# ECM3532 register map
Vendor: EtaCompute; Series: ECM35xx; File version: 1.0.0
CPU: CM3 r1p1, little endian, MPU, no FPU, 3 interrupt priority bits
Registers are 32-bit, read-write, reset 0x0 unless marked. A register's access mark holds for its fields unless they carry their own. Offsets are from the block's base; [hi:lo] are bit positions.

## I2C0 — I2C System Control Block Registers.
Base 0x50040000
Same registers: I2C1 0x50040080
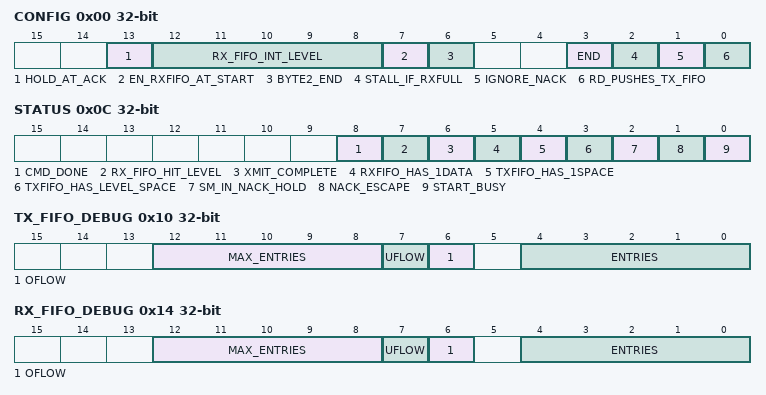
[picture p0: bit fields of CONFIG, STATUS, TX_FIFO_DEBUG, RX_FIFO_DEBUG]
0x00 CONFIG — I2C configuration register.
  [13] HOLD_AT_ACK — Setting this bit holds the SM before sending the clock for acknowledgement until an entry is placed in the TX FIFO or CMD FIFO. This allows for pathologically slow masters to not be required to avoid FIFO starvation on reads. For write operations there is no advantage to setting this bit, but the SM will still stop on ACK. Note that observers of the I2C lines will see see 8 bits of data followed by a pause and eventually the ACK, followed by the next 8 bits of data.
  [12:8] RX_FIFO_INT_LEVEL — Program to the level that you want RX_FIFO_HIT_LEVEL to be set. If this reg is 2, then RX_FIFO_HIT_LEVEL will be set if the number of entries in RX_FIFO are 2 or greater. Similarly this defines how many entries available in the TX FIFO for the TXFIFO_HAS_LEVEL_SPACE to be set.
  [7] EN_RXFIFO_AT_START — Typically, the RX FIFO requires a CMD fron the CMD_FIFO_DATA to enable RX FIFO. Setting this bit to 1 changes the default to 1. The RX FIFO can still be disabled using a CMD.
  [6] BYTE2_END — Only used for 2 or 4 byte transfers. If 0, DATA[15:8] is receive on SDA before DATA[7:0]. If 1, vice versa.
  [3] END — If 0, transmit msbit first. If 1 send lsbit first.
  [2] STALL_IF_RXFULL — If 1, the TX side will stall if RX FIFO is full.
  [1] IGNORE_NACK — If 0, an unexpected NACK will lockup the system and require a soft reset to exit. If 1, all NACKs are ignored.
  [0] RD_PUSHES_TX_FIFO — If set to 1, the TX FIFO will empty as normal, but for every read pop that occurs, a new TX will be pushed into the FIFO. This is good for DMA.
0x04 TXRX_1BYTE_FIFO_DATA — I2C read and write data register.
  [7:0] DATA — Reads return receive data from I2C. Writes send data to transmit of I2C.
0x0C STATUS — I2C status register. Note that ANDing this field with INT_EN will give you unmasked interrupts.
  [8] CMD_DONE ro — If 1, the command is done and the SM is idle. This is the inverse of START_BUSY provided here to make interrupt access cleaner.
  [7] RX_FIFO_HIT_LEVEL ro — If 1, then there is at least CONFIG.RX_FIFO_INT_LEVEL Byte(s) of data waiting in RX FIFO. Read TXRX_1BYTE_FIFO_DATA or RX_2BYTE_FIFO_DATA or RX_4BYTE_FIFO_DATA to get data.
  [6] XMIT_COMPLETE ro — If 1, all current transmits (data and cmd) are complete, but there may still be a command operation (e.g. stop) pending. See START_BUSY for a true end of command status.
  [5] RXFIFO_HAS_1DATA ro — If 1, then there is data waiting in RX FIFO. Read TXRX_1BYTE_FIFO_DATA to get data.
  [4] TXFIFO_HAS_1SPACE ro — If 1, then there is space to put onto the TX FIFO queue by writing to TXRX_1BYTE_FIFO_DATA. If 0, there isn't.
  [3] TXFIFO_HAS_LEVEL_SPACE ro — If 1, then there is space to put If 1, then there is at least CONFIG.RX_FIFO_INT_LEVEL Byte(s) of space available on TX_FIFO. If 0, there isn't.
  [2] SM_IN_NACK_HOLD ro — We have detected an unexpected NACK and the state machine has halted. It can be continued on with its original sequence by setting STATUS.NACK_ESCAPE or it can be reset by writing CONFIG.SOFT_RESET.
  [1] NACK_ESCAPE — If an unexpected NACK is received, the SM stalls allowing for debug. The SM can be unfrozen by writing 1 to this location after it is in the unexpected NACK stall and will continue with its previous command. Use CONFIG.SOFT_RESET to abort the command in progress.
  [0] START_BUSY — Write to 1 to start transaction. Read back to determine if the SM is START_BUSY (1) or if has gone back to idle (0).
0x10 TX_FIFO_DEBUG — I2C tx fifo debug register
  [12:8] MAX_ENTRIES ro — Depth of FIFO, i.e. the max number of entries possible in FIFO.
  [7] UFLOW ro — Set when TX FIFO underflows. Cleared by setting CONFIG2.CLR_STICKY
  [6] OFLOW ro — Set when TX FIFO overflows. Newest entries are dropped. Cleared by setting CONFIG2.CLR_STICKY
  [4:0] ENTRIES ro — Entries in FIFO.
0x14 RX_FIFO_DEBUG — I2C rx fifo debug register
  [12:8] MAX_ENTRIES ro — Depth of FIFO, i.e. the max number of entries possible in FIFO.
  [7] UFLOW ro — Set when TX FIFO underflows. Cleared by setting CONFIG2.CLR_STICKY
  [6] OFLOW ro — Set when TX FIFO overflows. See CONFIG.RX_OVFLW_KEEPHEAD for details on drop behavior. Cleared by setting CONFIG2.CLR_STICKY
  [4:0] ENTRIES ro — Entries in FIFO.
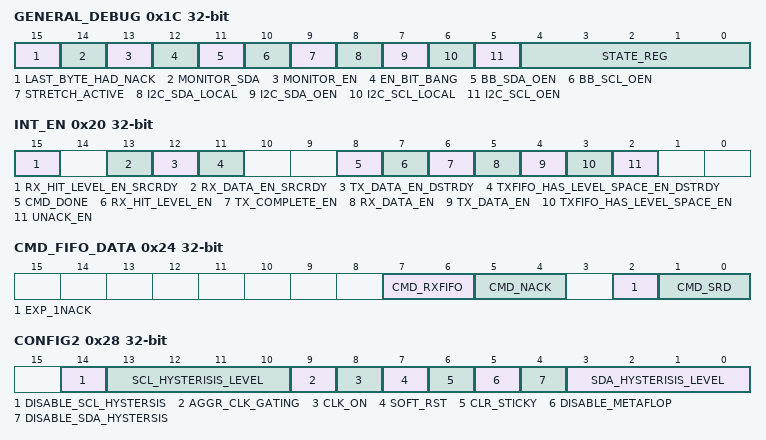
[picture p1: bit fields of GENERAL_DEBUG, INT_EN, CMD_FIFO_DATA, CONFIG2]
0x1C GENERAL_DEBUG — I2C General Debug Fields
  [15] LAST_BYTE_HAD_NACK ro — If 1, the last byte on the wire had a NACK. This bit is cleared and reevaluated when the state machine the next time the SM checks for a NACK (i.e. on the next byte). The bit will be set if the master or slave does not acknowlege for any reason.
  [14] MONITOR_SDA — If 0, we monitor SCL. If 1 we monitor SDA.
  [13] MONITOR_EN — If 0, the Rise Time debug monitor is disabled and the RISE_TIME_DEBUG.VALUE will be zeroed out. If 1, then the monitor records the time from the internal SDA_OEN or SCL_OEN (selected by MONITOR_SDA) to determine the rise time and effecetive pull stretngth of the external PUs. Each value in the monitor is a CLKIN. Note that the monitor will count delays from metastable flops or hystersis avoidance flops as additional rise time.
  [12] EN_BIT_BANG — If set, the BB_SDA_OEN, and BB_SCL_OEN control the I2C interface. The internal SM has no effect and can be placed in SOFT_RESET. However, the CONFIG2.CLK_ON bit should be set, or else the clock may gate off due to apparent quiescence.
  [11] BB_SDA_OEN — Value to drive on SDA_OEN. Signal is active low, so a 0 will drive I2C low. A high will let it float via PU to 1.
  [10] BB_SCL_OEN — Value to drive on SCL_OEN. Note that if SCL_CONFIG.HARD_DRIVE_SCL is set, this bit actually controlls SCL_OUT and SCL_OEN is set low (always driving)
  [9] STRETCH_ACTIVE ro — If this is set, the internal logic belives the SCL is being driven low by an external force (i.e. clock stretching)
  [8] I2C_SDA_LOCAL ro — Live input value of SDA (after meta stable and glitch filter flops)
  [7] I2C_SDA_OEN ro — Value of Output Enable (active low) of SDA. If nothing else is driving the line, this is what the line should be at steady state.
  [6] I2C_SCL_LOCAL ro — Live input value of SCL (after meta stable and glitch filter flops)
  [5] I2C_SCL_OEN ro — Value of Output Enable (active low) of SCL. If nothing else is driving the line, this is what the line should be at steady state.
  [4:0] STATE_REG ro — Current state of primary State Machine
0x20 INT_EN — I2C Interrupt Enable Registger. Note that ANDing this field with STATUS will give you unmasked interrupts.
  [15] RX_HIT_LEVEL_EN_SRCRDY — If set to 1, the STATUS field RX_FIFO_HIT_LEVEL will be accelerated into an interrupt for i2c_src_rdy. Reading from TXRX_1BYTE_FIFO_DATA will force the interrupt to go low for at least one cycle, perhaps more if the RX FIFO is now empty.
  [13] RX_DATA_EN_SRCRDY — If set to 1, the STATUS field RXFIFO_HAS_DATA will be accelerated into an interrupt for i2c_src_rdy. Reading from TXRX_1BYTE_FIFO_DATA will force the interrupt to go low for at least one cycle, perhaps more if the RX FIFO is now empty.
  [12] TX_DATA_EN_DSTRDY — If set to 1, the STATUS field TXFIFO_HAS_SPACE will be accelerated into an interrupt for i2c_dst_rdy. Writing to TXRX_1BYTE_FIFO_DATA will cause this to go low for at least one cycle, perhaps more if the TX FIFO fills.
  [11] TXFIFO_HAS_LEVEL_SPACE_EN_DSTRDY — If set to 1, the STATUS field TXFIFO_HAS_LEVEL_SPACE will be accelerated into an interrupt for i2c_dst_rdy. Writing to TXRX_1BYTE_FIFO_DATA or RX_2BYTE_FIFO_DATA or RX_4BYTE_FIFO_DATA will force the interrupt to go low for at least one cycle, perhaps more if the TX FIFO fills.
  [8] CMD_DONE — If set to 1, the STATUS field CMD_DONE going high will be accelerated into an interrupt for i2c_int. Note this will be high until the cmd is started. If the system is idle, there is no way to clear the interrupt other than disabling it here.
  [7] RX_HIT_LEVEL_EN — If set to 1, the STATUS field RX_FIFO_HIT_LEVEL will be accelerated into an interrupt for i2c_int. Reading from TXRX_1BYTE_FIFO_DATA will force the interrupt to go low for at least one cycle, perhaps more if the RX FIFO is now empty.
  [6] TX_COMPLETE_EN — If set to 1, the STATUS field XMIT_COMPLETE will be accelerated into an interrupt for i2c_int. Writing to TXRX_1BYTE_FIFO_DATA will cause this to go low for at least one cycle, perhaps more if the TX FIFO fills.
  [5] RX_DATA_EN — If set to 1, the STATUS field RXFIFO_HAS_DATA will be accelerated into an interrupt for i2c_int. Reading from TXRX_1BYTE_FIFO_DATA will force the interrupt to go low for at least one cycle, perhaps more if the RX FIFO is now empty.
  [4] TX_DATA_EN — If set to 1, the STATUS field TXFIFO_HAS_SPACE will be accelerated into an interrupt for i2c_int. Writing to TXRX_1BYTE_FIFO_DATA will cause this to go low for at least one cycle, perhaps more if the TX FIFO fills.
  [3] TXFIFO_HAS_LEVEL_SPACE_EN — If set to 1, the STATUS field TXFIFO_HAS_LEVEL_SPACE will be accelerated into an interrupt for i2c_int. Writing to TXRX_1BYTE_FIFO_DATA or RX_2BYTE_FIFO_DATA or RX_4BYTE_FIFO_DATA will force the interrupt to go low for at least one cycle, perhaps more if the TX FIFO fills.
  [2] UNACK_EN — If set to 1, the STATUS field SM_IN_NACK_HOLD will be accelerated into an interrupt for i2c_int. Note this will be high until the NACK is processed either with a STATUS.NACK_ESCAPE or a CONFIG2.SOFT_RESET
0x24 CMD_FIFO_DATA — I2C command FIFO. Writes to this FIFO go into the TX_FIFO and are executed in series with the DATA pushed in TXRX_1BYTE_FIFO_DATA. By using the CMD and DATA entries, different sequences can be setup to imelement write, read commands, as well as start / stop seqeuences. Note that the commands generally take effect around the ACK time for the PREVIOUS byte. Multiple commands can be combined into a single write with the exception of the dummy byte, which must be a command by itself. As an example, a Adesto RM24C32C is a SEEPROM that uses 2 address bytes (called A0 and A1) below. Assuming it has its device address bits configured as 0, then a typical write of two bytes of data (0xD0, 0xD1) command would be: Write 0xa4 to TXRX_1BYTE_FIFO_DATA // Device ID, Write Write 0xa0 to TXRX_1BYTE_FIFO_DATA // SEEPROM Address Write 0xa1 to TXRX_1BYTE_FIFO_DATA // SEEPROM Address Write 0xd0 to TXRX_1BYTE_FIFO_DATA // Data0 Write 0xd1 to TXRX_1BYTE_FIFO_DATA // Data1 Write 0x04 to CMD_FIFO_DATA // Issue STOP A typical random read (which involes writing the desired address and then triggering a restart to read the data) of the same data would be: Write 0xa4 to TXRX_1BYTE_FIFO_DATA // Device ID, Write Write 0xa0 to TXRX_1BYTE_FIFO_DATA // SEEPROM Address Write 0xa1 to TXRX_1BYTE_FIFO_DATA // SEEPROM Address Write 0x01 to CMD_FIFO_DATA // Issue Restart Write 0xa5 to TXRX_1BYTE_FIFO_DATA // Device ID, Read Write 0xff to TXRX_1BYTE_FIFO_DATA // Dummy data (will be filled in by remote side) Write 0xd0 to CMD_FIFO_DATA // Issue command to drive NACK to 0 and enable RX FIFO Write 0xff to TXRX_1BYTE_FIFO_DATA // Dummy data (will be filled in by remote side) Write 0x34 to CMD_FIFO_DATA // Send NACK=1 on last read and issue STOP For longer reads, it is probably peferable to use the dummy byte cmd to fill in the dummy data. However, note that to trigger the NACKs and other commands correctly, the first and probably last dummy data should be manually entered (last is optional, but it is considered good protocol to issue a NACK=1 on the last byte of data read by master).
  [7:6] CMD_RXFIFO — Controls when data on the I2C line is driven into RX_FIFO.
    0=NOTHING (Leave NACK at its previous state. When STATUS.START_BUSY is written, the NACK bit is set high meaning the master will not drive the NACK low to acknowledge.); 1=DISABLE_RXFIFO (All bytes received AFTER this command will be not be sent to the RX_FIFO.); 3=ENABLE_RXFIFO (All bytes received AFTER this command will bebe sent into the RX_FIFO. Typically used for reads.)
  [5:4] CMD_NACK — Controls the master driving the NACK bit.
    0=NOTHING (Leave NACK at its previous state. When STATUS.START_BUSY is written, the NACK bit is set high meaning the master will not drive the NACK low to acknowledge.); 1=DRIVE_NACK_LOW (All bytes from this point forward will be acknowledged by the master (typically used for reads)); 3=DRIVE_NACK_HIGH (All bytes from this point forward will not be acknowledged by the master (typically used for the last read which is NACK'd to tell slave we're done reading))
  [2] EXP_1NACK — Writes this bit to ignore a negative ACK for the PREVIOUS data transfer. Not that this is required if the slave does not acknlowedge or if the master does not set the ACK bit low. Without this bit, an unexpected NACK will land the SM in a hold state (see STATUS.SM_IN_NACK_HOLD for more details).
  [1:0] CMD_SRD — These two bits control sending either a STOP, RESTART or a set of dummy bytes. Obviously, you can only send one of the three (or send nothing).
    0=NOTHING (Finish current data byte and begin an I2C RESTART sequence.); 1=RESTART (Finish current data byte and begin an I2C RESTART sequence.); 2=STOP (Finish current data byte and begin an I2C STOP sequence.); 3=DUMMYBYTE (If this is set, DUMMY_BYTES worth of dummy bytes (0xff) are "transmitted". This is very useful for read operations where you need to trigger a number of byte transfers, but you don't want to feed 1 byte into the TX_FIFO for each one. Once this command is set, the DUMMY bytes will fill the TX FIFO. Until those bytes finish, it is dangerous to write to the CMD FIFO, the DATA FIFO or to the DUMMY_BYTES register.)
0x28 CONFIG2 — I2C configuration2 register.
  [14] DISABLE_SCL_HYSTERSIS — 0 is the normal, recommended flow. If 1, all SCL hysterisis is disabled. See SCL_HYSTERISIS_LEVEL for more info.
  [13:10] SCL_HYSTERISIS_LEVEL — Due to the nature of I2C, the signals are susceptible to noise, especially during the I2C "high" when it is weakly driven by a pull up resistor. The IP supports a hysterisis module that samples the input SDA and SCL signal signals to ensure they are stable before seen by the internal logic. This glitch avoidance circuit adds latency to the receive signals, which can slow down the overall I2C period. For this reason, the hysterisys level is configureable from this register. Set to 0x0 to get the full 16 CLK hysterisis, 0x1 for 15 CLK hystersis, 0x2 for 14 CLK hysteris and up to value 0xf for 1 CLK hysteris. To fully disable hystersis, set DISABLE_SCL_HYSTERSIS
  [9] AGGR_CLK_GATING — If set to 1, a more aggressive clock gating scheme is enacted that will clock the gate even if the command is still in flight, but the FIFOs, etc. have emptied (i.e. processor has starved FIFOs). If 0, we only gate when the command is complete.
  [8] CLK_ON — This bit provides an override to the clock gate enable. If 0, the clock will only run if the local state machine is busy. If 1, the clock will always run.
  [7] SOFT_RST — If 1, all FIFO / SM in I2C will be held in reset. If 0, normal operation. To do a soft reset, you must write this to 1 and then back to 0 to remove the reset.
  [6] CLR_STICKY — If 1, clear sticky bits in registers. If 0, normal operation. To do a soft reset, you must write this to 1 and then back to 0 to remove the reset.
  [5] DISABLE_METAFLOP — 0 is the normal, recommended flow. If 1, the 2 CLKIN delay of SDA and SCL is bypassed allowing for faster operation at the risk of metastablity if SDA and SCL changes near sample time. Normally SDA and SCL should change with >100 ns setup / hold, so it may be a viable risk.
  [4] DISABLE_SDA_HYSTERSIS — 0 is the normal, recommended flow. If 1, all SDA hysterisis is disabled. See SDA_HYSTERISIS_LEVEL for more info.
  [3:0] SDA_HYSTERISIS_LEVEL — Due to the nature of I2C, the signals are susceptible to noise, especially during the I2C "high" when it is weakly driven by a pull up resistor. The IP supports a hysterisis module that samples the input SDA and SCL signal signals to ensure they are stable before seen by the internal logic. This glitch avoidance circuit adds latency to the receive signals, which can slow down the overall I2C period. For this reason, the hysterisys level is configureable from this register. Set to 0x0 to get the full 16 CLK hysterisis, 0x1 for 15 CLK hystersis, 0x2 for 14 CLK hysteris and up to value 0xf for 1 CLK hysteris. To fully disable hystersis, set DISABLE_SDA_HYSTERSIS
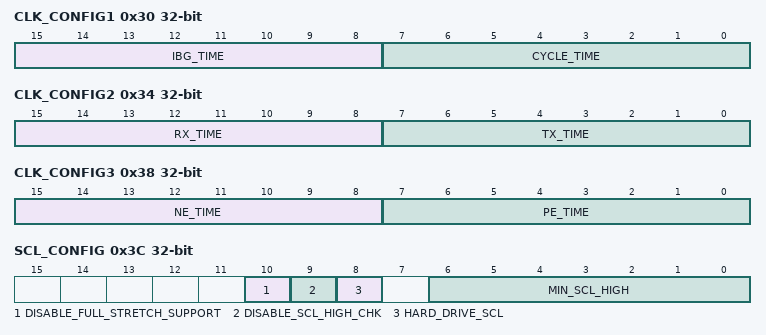
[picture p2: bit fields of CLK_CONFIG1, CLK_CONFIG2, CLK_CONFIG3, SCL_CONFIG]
0x30 CLK_CONFIG1 — I2C Clock Config Register 1
  [15:8] IBG_TIME — The delay bewteen each byte will be (IBG_TIME+1) * CLKIN period (125ns).
  [7:0] CYCLE_TIME — Controls I2C clock rate. Several registers control the I2C clock speeds giving maximum flexibility. Each register defines the time that an I2C event occurs on against a counter going from 0 to cycle_time. Legitimate values for each counter are from 0 to 127. Each bit is an additional CLKIN cycle (125ns). The overal speed is derived from the cycle_time, so if cycle_time is 0x4f, then the overall period would be (0x4f+1)*125ns = 10us or a 100KHz period. There are registers to control when I2C_CLK is driven high (pe_time) and when to drive the I2C_CLK low (ne_time). There are registers to define when data is driven onto the line from the IP (tx_time), when data from the remote slave is sampled (rx_time). The values in these registers should be programmed according to I2C protocol, e.g. setting tx_time in between pe_time and ne_time would likely not be productive. Additionally, there is an inter byte gap time (ibg_time). Nothing in the logic checks for incorrect values. Assuming CLKIN is 4MHz, this would be a reasonable configuration for 100KHz. cycle_time = 0x27 pe_time = 0x10 ne_time = 0x1f tx_time = 0x01 rx_time = 0x19 min_scl = 0x04 hyst_level = 0x08 Assuming CLKIN is 4MHz, this would be a reasonable configuration for 400KHz. cycle_time = 0x09 pe_time = 0x04 ne_time = 0x08 tx_time = 0x01 rx_time = 0x05 min_scl = 0x00 hyst_level = 0x01 Note that the follow events are derived from csr times in the sequence START_SDA_LOW - pe_time START_SCL_LOW - ne_time STOP_SDA_HIGH - tx_time STOP_SCL_HIGH - pe_time
0x34 CLK_CONFIG2 — I2C Clock Config Register 2
  [15:8] RX_TIME — See CLK_CYCLE.TIME_VAL.
  [7:0] TX_TIME — See CLK_CYCLE.TIME_VAL.
0x38 CLK_CONFIG3 — I2C Clock Config Register 3
  [15:8] NE_TIME — See CLK_CYCLE.TIME_VAL.
  [7:0] PE_TIME — See CLK_CYCLE.TIME_VAL.
0x3C SCL_CONFIG — I2C SCL Config Register
  [10] DISABLE_FULL_STRETCH_SUPPORT — This is a debug bit and should not be set under normal circumstances.
  [9] DISABLE_SCL_HIGH_CHK — If this bit is set, then the logic ignore the current input state of the SCL and by extention, disable the metastability FF on the SCL.
  [8] HARD_DRIVE_SCL — If this bit is cleared,the SCL is driven low and then a weak PU pulls the SCL high. If this bit is set the SCL will be driven low and high. This allows for better defined rise times on SCL and for the removal of a potentially low resistance PU on the SCL line. However, if this bit is set it effectively disables clock stretching.
  [6:0] MIN_SCL_HIGH — In the case where clock stretching deforms the programmed release of SCL so it is pulled high, the SCL can have a much shorter width. This register defines that minimum width. Note that the metastable FF (1 to 2 clocks) and glitch avoidance logic (0-16 clocks) and the MIN_SCL_HIGH are effectively added together to form the SCL high as seen by the outside world. So if the glitch avoidance is set to 16 and CLKIN is 8MHz, then the SCL will be high for at least 2.125 ns plus 125ns * MIN_SCLK_HIGH.
0x40 RX_2BYTE_FIFO_DATA — I2C read and write data register.
  [15:0] DATA — 2 byte reads return receive data from I2C. Writes have no effect. By default, data is returned little endian so bit [7:0] will have the first byte that was received, bit [15:8] will have the second byte received. By setting CONFIG.BYTE2_END, this order can be reversed.
0x44 RX_4BYTE_FIFO_DATA — I2C read data register. Note this register is disabled in DSP instances.
  [31:0] DATA — 4 byte reads return receive data from I2C. Writes have no effect. By default, data is returned little endian so bit [7:0] will have the first byte that was received, bit [15:8] will have the second byte received, etc. up to bit [31:24] having the fourth byte received. By setting CONFIG.BYTE2_END, this order can be reversed.
0x48 RISE_TIME_DEBUG — I2C rise debug register
  [7:0] VALUE ro — When Monitor Enabled, this is the most recent time
0x4C DUMMY_BYTES — I2C Dummy byte register
  [15:0] VALUE — This is the number of dummy bytes to send when called out in the CMD_FIFO_DATA when CMD_STOP_RESTART_DUMMY is set to DUMMYBYTE. At that point, the DATA FIFO and CMD will begin to be filled with dummy bytes (0xff) and will not be available for writes until the dummy bytes complete. You can read this register to determine when all of the dummy bytes are pushed into the FIFO or STATUS.XMIT_COMPLETE for when the entire TX_FIFO has transmitted its data. Modifying this value after the DUMMYBYTE command has been issued has an unknown effect.
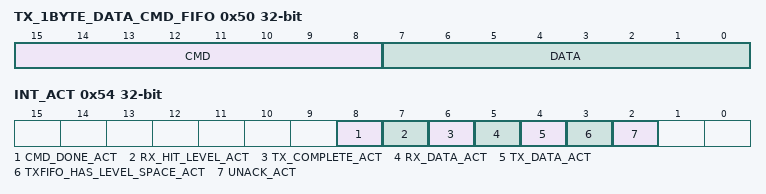
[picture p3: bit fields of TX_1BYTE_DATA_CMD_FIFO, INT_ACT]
0x50 TX_1BYTE_DATA_CMD_FIFO — Note this register is only enabled in DSP instances and is intended to support DMA transactions. Writing this register has a similar effect to writing TXRX_1BYTE_FIFO_DATA followed by a write to CMD_FIFO_DATA, but it is done in a single write. Note that if the CMD is all 0 (i.e. a nop), this does not actually push an entry onto the CMD_FIFO. Note too that a single write to this register can push two entries onto the FIFO, so be sure to have at least 2 entries in FIFO before writing
  [15:8] CMD — A non-zero write to this location is similar to writing it to CMD_FIFO_DATA. A all zero write has no effect. Reads return all 0.
  [7:0] DATA — Write data to this location is similar to writing it to TXRX_1BYTE_FIFO_DATA. Reads return all 0.
0x54 INT_ACT — I2C Active Interrupts. This is effectively STATUS ANDed with INT_EN
  [8] CMD_DONE_ACT ro — STATUS.CMD_DONE is set and active
  [7] RX_HIT_LEVEL_ACT ro — STATUS.RX_FIFO_HIT_LEVEL is set and active
  [6] TX_COMPLETE_ACT ro — STATUS.XMIT_COMPLETE is set and active
  [5] RX_DATA_ACT ro — STATUS.RXFIFO_HAS_DATA is set and active
  [4] TX_DATA_ACT ro — STATUS.TXFIFO_HAS_SPACE is set and active
  [3] TXFIFO_HAS_LEVEL_SPACE_ACT ro — STATUS.TXFIFO_HAS_LEVEL_SPACE is set and active
  [2] UNACK_ACT ro — STATUS.SM_IN_NACK_HOLD is set and active
